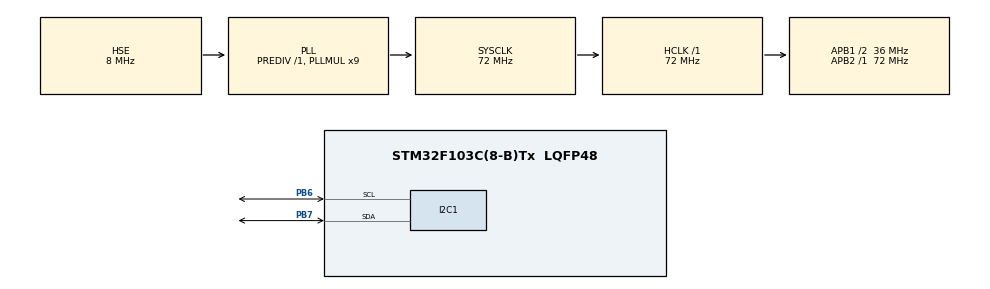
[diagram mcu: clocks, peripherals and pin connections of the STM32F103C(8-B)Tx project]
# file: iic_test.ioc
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Mcu.Family=STM32F1
Mcu.Name=STM32F103C(8-B)Tx
Mcu.Package=LQFP48
NVIC.PriorityGroup=NVIC_PRIORITYGROUP_4
PA13.Mode=Serial_Wire
PA13.Signal=SYS_JTMS-SWDIO
PA14.Mode=Serial_Wire
PA14.Signal=SYS_JTCK-SWCLK
PB6.Mode=I2C
PB6.Signal=I2C1_SCL
PB7.Mode=I2C
PB7.Signal=I2C1_SDA
PD0-OSC_IN.Mode=HSE-External-Oscillator
PD0-OSC_IN.Signal=RCC_OSC_IN
PD1-OSC_OUT.Mode=HSE-External-Oscillator
PD1-OSC_OUT.Signal=RCC_OSC_OUT
ProjectManager.HeapSize=0x200
ProjectManager.StackSize=0x400
ProjectManager.TargetToolchain=MDK-ARM V5.32
RCC.AHBFreq_Value=72000000
RCC.APB1CLKDivider=RCC_HCLK_DIV2
RCC.APB1Freq_Value=36000000
RCC.APB1TimFreq_Value=72000000
RCC.APB2Freq_Value=72000000
RCC.APB2TimFreq_Value=72000000
RCC.HCLKFreq_Value=72000000
RCC.PLLMUL=RCC_PLL_MUL9
RCC.PLLSourceVirtual=RCC_PLLSOURCE_HSE
RCC.SYSCLKFreq_VALUE=72000000
RCC.SYSCLKSource=RCC_SYSCLKSOURCE_PLLCLK
RCC.USBFreq_Value=72000000
board=custom

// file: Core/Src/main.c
/* USER CODE BEGIN Header */
/**
  ******************************************************************************
  * @file           : main.c
  * @brief          : Main program body
  ******************************************************************************
  * @attention
  *
  * Copyright (c) 2023 STMicroelectronics.
  * All rights reserved.
  *
  * This software is licensed under terms that can be found in the LICENSE file
  * in the root directory of this software component.
  * If no LICENSE file comes with this software, it is provided AS-IS.
  *
  ******************************************************************************
  */
/* USER CODE END Header */
#include "main.h"
#include "i2c.h"
#include "gpio.h"

/* USER CODE BEGIN PV */
unsigned char peiqi[]=
{
0x00,0x00,0x00,0x00,0x00,0x00,0x00,0x00,0xC0,0x30,0x90,0x50,0x50,0x90,0x20,0x7E,
0xC1,0x1D,0x64,0x44,0x79,0x02,0xBC,0x90,0xD0,0x50,0x90,0x88,0x28,0x68,0xA8,0x28,
0xA8,0x04,0xE4,0x54,0x54,0x64,0x68,0x48,0x90,0x20,0xC0,0x00,0x00,0x00,0x00,0x00,
0x00,0x00,0x00,0x00,0x00,0x00,0x00,0x00,0x00,0x00,0x00,0x00,0x00,0x00,0x00,0x00,
0x00,0x00,0x00,0x00,0x00,0x00,0x00,0x00,0x00,0x00,0x00,0x00,0x00,0x00,0x00,0x00,
0x00,0x00,0x00,0x00,0x00,0x00,0x00,0x00,0x00,0x00,0x00,0x00,0x00,0x00,0x00,0x00,
0x00,0x00,0x00,0x00,0x00,0x00,0x00,0x00,0x00,0x00,0x00,0x00,0x00,0x00,0x00,0x00,
0x00,0x00,0x00,0x00,0x00,0x00,0x00,0x00,0x00,0x00,0x00,0x00,0x00,0x00,0x00,0x00,
0x00,0x00,0x00,0x00,0x00,0x00,0x00,0x00,0x03,0x04,0xC9,0x32,0x84,0x65,0x13,0x08,
0x05,0x3C,0x46,0x92,0x81,0x05,0xB9,0x83,0x6C,0x10,0x10,0x14,0x17,0x20,0x0C,0x03,
0x07,0x08,0x13,0xA4,0xAC,0x4A,0x12,0x92,0x4F,0x20,0x0F,0x00,0x00,0x00,0x00,0x00,
0x00,0x00,0x00,0x00,0x00,0x00,0x00,0x00,0x00,0x00,0x00,0x00,0x00,0x00,0x00,0x00,
0x00,0x00,0x00,0x00,0x00,0x00,0x00,0x00,0x00,0x00,0x00,0x00,0x00,0x00,0x00,0x00,
0x00,0x00,0x00,0x00,0x00,0x00,0x00,0x00,0x00,0x00,0x00,0x00,0x00,0x00,0x00,0x00,
0x00,0x00,0x00,0x00,0x00,0x00,0x00,0x00,0x00,0x00,0x00,0x00,0x00,0x00,0x00,0x00,
0x00,0x00,0x00,0x00,0x00,0x00,0x00,0x00,0x00,0x00,0x00,0x00,0x00,0x00,0x00,0x00,
0x00,0x00,0x00,0x00,0x00,0x00,0x00,0x00,0xF8,0x07,0xF0,0xFE,0x04,0x72,0x88,0x09,
0x0A,0x8A,0x64,0x08,0xF0,0x80,0x00,0x00,0x00,0x00,0x00,0x00,0x00,0x00,0xC0,0x04,
0xCA,0x71,0x85,0x3C,0xC2,0x02,0x01,0x00,0x00,0x00,0x00,0x00,0x00,0x00,0x00,0x00,
0x00,0x00,0x00,0x00,0x00,0x00,0x00,0x00,0x00,0x00,0x00,0x00,0x00,0x00,0x00,0x00,
0x00,0x00,0x00,0x00,0x00,0x00,0x00,0x00,0x00,0x00,0x00,0x00,0x00,0x00,0x00,0x00,
0x00,0x00,0x00,0x00,0x00,0x00,0x00,0x00,0x00,0x00,0x00,0x00,0x00,0x00,0x00,0x00,
0x00,0x00,0x00,0x00,0x00,0x00,0x00,0x00,0x00,0x00,0x00,0x00,0x00,0x00,0x00,0x00,
0x00,0x00,0x00,0x00,0x00,0x00,0x00,0x00,0x00,0x00,0x00,0x00,0x00,0x00,0x00,0x00,
0x00,0x00,0x00,0x00,0x00,0x00,0x00,0x00,0x03,0x1C,0x61,0x8E,0x13,0x44,0x84,0x85,
0x05,0x04,0x02,0x01,0x03,0x04,0x09,0x1A,0x12,0x14,0x14,0x14,0x12,0x8B,0x48,0x82,
0xB1,0x4C,0xE3,0x1C,0x0F,0x00,0x00,0x00,0x00,0x00,0x00,0x00,0x00,0x00,0x00,0x00,
0x00,0x00,0x00,0x00,0x00,0x00,0x00,0x00,0x00,0x00,0x00,0x00,0x00,0x00,0x00,0x06,
0x06,0x00,0x00,0x00,0x00,0x00,0x00,0x00,0x00,0x00,0x00,0x00,0x00,0x00,0x00,0x00,
0x00,0x00,0x00,0x00,0x00,0x00,0x00,0x00,0x00,0x00,0x00,0x00,0x00,0x00,0x00,0x00,
0x00,0x00,0x00,0x00,0x00,0x00,0x00,0x00,0x00,0x00,0x00,0x00,0x00,0x00,0x00,0x00,
0x00,0x00,0x00,0x00,0x00,0x00,0x00,0x00,0x00,0x00,0x00,0x00,0x00,0x00,0x00,0x00,
0xF0,0x08,0x08,0x48,0x08,0xA8,0x84,0x54,0xC4,0x62,0x02,0xE3,0x1C,0x06,0x02,0x04,
0x05,0x09,0x0A,0x0A,0x0A,0x02,0x0A,0x0A,0x1A,0x19,0x01,0x05,0x04,0x02,0x02,0x01,
0x03,0x0C,0x71,0x82,0x22,0xC4,0x54,0x44,0xA8,0x08,0x68,0x08,0x08,0x40,0x10,0x00,
0x00,0x00,0x00,0x00,0x00,0x00,0x00,0x00,0x00,0x00,0x00,0x00,0x00,0x00,0x00,0x00,
0x00,0x00,0x00,0x00,0x00,0x00,0x00,0x00,0x00,0x00,0x00,0x00,0x00,0x00,0x00,0x00,
0x00,0x00,0x00,0x00,0x00,0x00,0x00,0x00,0x00,0x00,0x00,0x00,0x00,0x00,0x00,0x00,
0x00,0x00,0x00,0x00,0x00,0x00,0x00,0x00,0x00,0x00,0x00,0x00,0x00,0x00,0x00,0x00,
0x00,0x00,0x00,0x00,0x00,0x00,0x00,0x00,0x00,0x00,0x00,0x00,0x00,0x00,0x00,0x00,
0x31,0x4A,0x8A,0x06,0x12,0x83,0xA2,0x84,0x07,0xE0,0x0F,0x00,0x00,0x00,0x00,0x00,
0x00,0x00,0x00,0x00,0x00,0x00,0x00,0x00,0x00,0x00,0x00,0x00,0x00,0x00,0x00,0x00,
0x00,0x00,0x00,0x07,0xF8,0x03,0x3C,0xE0,0x00,0x00,0x02,0x01,0x02,0x00,0x00,0x00,
0x00,0x00,0x00,0x00,0x00,0x00,0x00,0x00,0x00,0x00,0x00,0x00,0x00,0x00,0x00,0x00,
0x00,0x00,0x00,0x00,0x00,0x00,0x00,0x00,0x00,0x00,0x00,0x00,0x00,0x00,0x00,0x00,
0x00,0x00,0x00,0x00,0x00,0x00,0x00,0x00,0x00,0x00,0x00,0x00,0x00,0x00,0x00,0x00,
0x00,0x00,0x00,0x00,0x00,0x00,0x00,0x00,0x00,0x00,0x00,0x00,0x00,0x00,0x00,0x00,
0x00,0x00,0x00,0x00,0x00,0x00,0x00,0x00,0x00,0x00,0x00,0x00,0x00,0x00,0x00,0x00,
0x00,0x00,0x00,0x01,0x01,0x00,0x0C,0x03,0x10,0x17,0x14,0x14,0x14,0xD4,0x34,0x84,
0x04,0xF4,0x14,0x14,0x14,0x14,0x14,0x14,0x14,0x14,0x14,0x14,0xF4,0x04,0xC4,0x04,
0xF4,0x94,0x54,0x54,0x54,0x57,0x10,0x4F,0xA0,0x40,0x00,0x00,0x00,0x00,0x00,0x00,
0x00,0x00,0x00,0x00,0x00,0x00,0x00,0x00,0x00,0x00,0x00,0x00,0x00,0x00,0x00,0x00,
0x00,0x00,0x00,0x00,0x00,0x00,0x00,0x00,0x00,0x00,0x00,0x00,0xC0,0xC0,0x00,0x00,
0x00,0x00,0x00,0x00,0x00,0x00,0x00,0x00,0x00,0x00,0x00,0x00,0x00,0x00,0x00,0x00,
0x00,0x00,0x00,0x00,0x00,0x00,0x00,0x00,0x00,0x00,0x00,0x00,0x00,0x00,0x00,0x00,
0x00,0x00,0x00,0x00,0x00,0x00,0x00,0x00,0x00,0x00,0x00,0x00,0x00,0x00,0x00,0x00,
0x00,0x00,0x00,0x00,0x00,0x00,0x00,0x00,0x00,0x00,0x00,0x00,0x06,0x01,0x08,0x08,
0x10,0x15,0x15,0x15,0x15,0x11,0x0C,0x00,0x00,0x00,0x00,0x00,0x07,0x08,0x00,0x08,
0x0A,0x0A,0x0A,0x0A,0x08,0x00,0x01,0x90,0x90,0x00,0x80,0x80,0x90,0x90,0x80,0x20,
0x00,0x00,0x00,0x00,0x00,0x00,0x00,0x00,0x00,0x00,0x00,0x00,0x00,0x00,0x00,0x00,
0x00,0x00,0x00,0x00,0x00,0x00,0x00,0x00,0x00,0x00,0x00,0x00,0x00,0x00,0x00,0x00,
0x00,0x00,0x00,0x00,0x00,0x00,0x00,0x00,0x00,0x00,0x00,0x00,0x00,0x00,0x00,0x00,
0x00,0x00,0x00,0x00,0x00,0x00,0x00,0x00,0x00,0x00,0x00,0x00,0x00,0x00,0x00,0x00,
0x00,0x00,0x00,0x00,0x00,0x00,0x00,0x00,0x00,0x00,0x00,0x00,0x00,0x00,0x00,0x00,
};
/* USER CODE END PV */

void SystemClock_Config(void);

/* USER CODE BEGIN 0 */

/**
  * @brief  Write an amount of data in blocking mode to a specific memory address
  * @param  hi2c Pointer to a I2C_HandleTypeDef structure that contains
  *                the configuration information for the specified I2C.
  * @param  DevAddress Target device address: The device 7 bits address value
  *         in datasheet must be shifted to the left before calling the interface
  * @param  MemAddress Internal memory address
  * @param  MemAddSize Size of internal memory address
  * @param  pData Pointer to data buffer
  * @param  Size Amount of data to be sent
  * @param  Timeout Timeout duration
  * @retval HAL status
  */

void iic_write_cmd(uint8_t cmd) {
	HAL_I2C_Mem_Write(&hi2c1, 0x78, 0x00, I2C_MEMADD_SIZE_8BIT,
										&cmd, 1, 0xff);
}

void iic_write_data(uint8_t data) {
	HAL_I2C_Mem_Write(&hi2c1, 0x78, 0x40, I2C_MEMADD_SIZE_8BIT,
										&data, 1, 0xff);
}

void oled_init() {
	iic_write_cmd(0xAE);//--display off
	iic_write_cmd(0x00);//---set low column address
	iic_write_cmd(0x10);//---set high column address
	iic_write_cmd(0x40);//--set start line address
	iic_write_cmd(0xB0);//--set page address
	iic_write_cmd(0x81); // contract control
	iic_write_cmd(0xFF);//--128
	iic_write_cmd(0xA1);//set segment remap
	iic_write_cmd(0xA6);//--normal / reverse
	iic_write_cmd(0xA8);//--set multiplex ratio(1 to 64)
	iic_write_cmd(0x3F);//--1/32 duty
	iic_write_cmd(0xC8);//Com scan direction
	iic_write_cmd(0xD3);//-set display offset
	iic_write_cmd(0x00);//

	iic_write_cmd(0xD5);//set osc division
	iic_write_cmd(0x80);//

	iic_write_cmd(0xD8);//set area color mode off
	iic_write_cmd(0x05);//

	iic_write_cmd(0xD9);//Set Pre-Charge Period
	iic_write_cmd(0xF1);//

	iic_write_cmd(0xDA);//set com pin configuartion
	iic_write_cmd(0x12);//

	iic_write_cmd(0xDB);//set Vcomh
	iic_write_cmd(0x30);//

	iic_write_cmd(0x8D);//set charge pump enable
	iic_write_cmd(0x14);//

	iic_write_cmd(0xAF);//--turn on oled panel
}

void oled_clear() {
	int i, j;
	for(i = 0; i < 8; i ++) {
		iic_write_cmd(0xB0+i);
		iic_write_cmd(0x00);
		iic_write_cmd(0x10);
		for(j = 0; j < 128; j ++) {
			iic_write_data(0);
		}
	}
}

void oled_image(unsigned char *image)
{
	unsigned char i;
	unsigned int j;

	for(i=0;i<8;i++){
		iic_write_cmd(0xB0 + i);
		iic_write_cmd(0x00);
		iic_write_cmd(0x10);

		for(j = 128 * i; j<(128 * (i+1));j++){
			iic_write_data(image[j]);
		}
	}
}

/* USER CODE END 0 */

int main(void)
{

  /* MCU Configuration--------------------------------------------------------*/

  /* Reset of all peripherals, Initializes the Flash interface and the Systick. */
  HAL_Init();

  /* Configure the system clock */
  SystemClock_Config();

  /* Initialize all configured peripherals */
  MX_GPIO_Init();
  MX_I2C1_Init();
  /* USER CODE BEGIN 2 */

	oled_init();

	// 3、addressing setting command table 第三行
	iic_write_cmd(0x20);
	iic_write_cmd(0x02);

	oled_clear();

	oled_image(peiqi);

  /* USER CODE END 2 */

  /* Infinite loop */
  while (1)
  {

  }
}

void SystemClock_Config(void)
{
  RCC_OscInitTypeDef RCC_OscInitStruct = {0};
  RCC_ClkInitTypeDef RCC_ClkInitStruct = {0};

  /** Initializes the RCC Oscillators according to the specified parameters
  * in the RCC_OscInitTypeDef structure.
  */
  RCC_OscInitStruct.OscillatorType = RCC_OSCILLATORTYPE_HSE;
  RCC_OscInitStruct.HSEState = RCC_HSE_ON;
  RCC_OscInitStruct.HSEPredivValue = RCC_HSE_PREDIV_DIV1;
  RCC_OscInitStruct.HSIState = RCC_HSI_ON;
  RCC_OscInitStruct.PLL.PLLState = RCC_PLL_ON;
  RCC_OscInitStruct.PLL.PLLSource = RCC_PLLSOURCE_HSE;
  RCC_OscInitStruct.PLL.PLLMUL = RCC_PLL_MUL9;
  if (HAL_RCC_OscConfig(&RCC_OscInitStruct) != HAL_OK)
  {
    Error_Handler();
  }

  /** Initializes the CPU, AHB and APB buses clocks
  */
  RCC_ClkInitStruct.ClockType = RCC_CLOCKTYPE_HCLK|RCC_CLOCKTYPE_SYSCLK
                              |RCC_CLOCKTYPE_PCLK1|RCC_CLOCKTYPE_PCLK2;
  RCC_ClkInitStruct.SYSCLKSource = RCC_SYSCLKSOURCE_PLLCLK;
  RCC_ClkInitStruct.AHBCLKDivider = RCC_SYSCLK_DIV1;
  RCC_ClkInitStruct.APB1CLKDivider = RCC_HCLK_DIV2;
  RCC_ClkInitStruct.APB2CLKDivider = RCC_HCLK_DIV1;

  if (HAL_RCC_ClockConfig(&RCC_ClkInitStruct, FLASH_LATENCY_2) != HAL_OK)
  {
    Error_Handler();
  }
}

void Error_Handler(void)
{
  __disable_irq();
  while (1)
  {
  }
}
